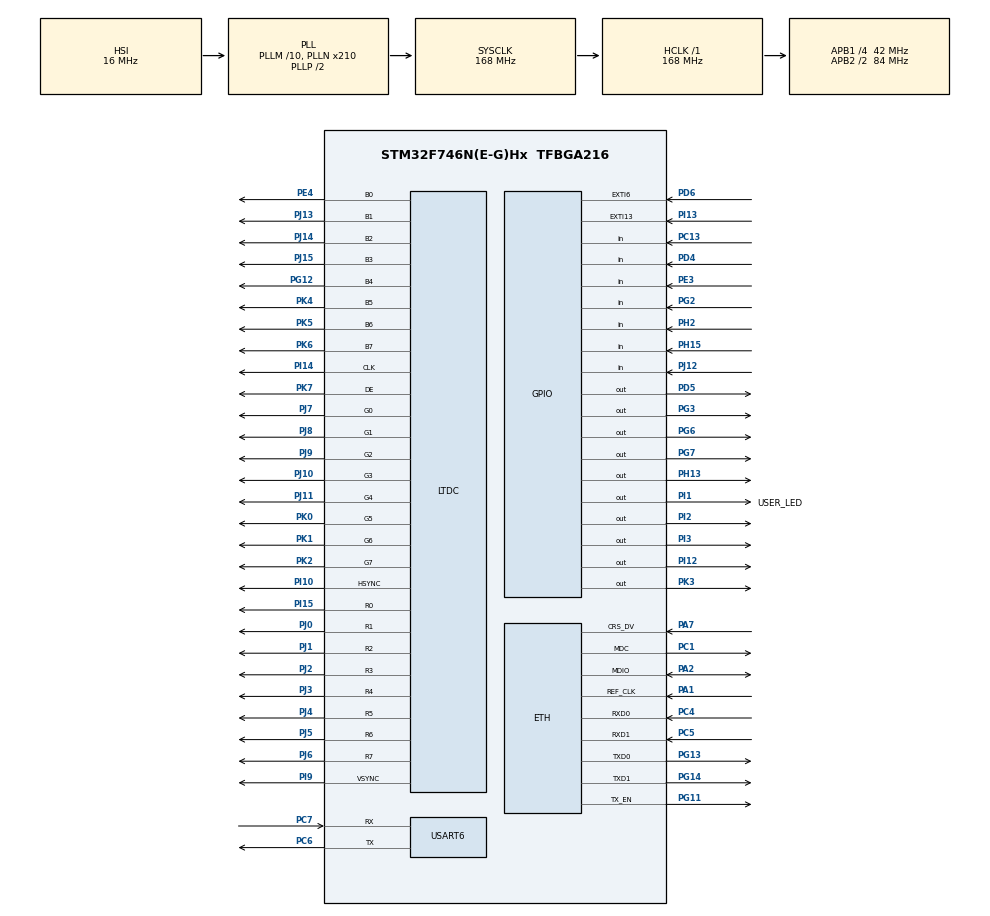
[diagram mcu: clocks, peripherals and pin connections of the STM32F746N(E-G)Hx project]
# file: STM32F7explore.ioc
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ETH.MediaInterface=ETH_MEDIA_INTERFACE_RMII
FREERTOS.Tasks01=defaultTask,0,128,StartDefaultTask,Default,NULL,Dynamic,NULL,NULL;BlinkyTask,-3,128,ExecBlinkyTask,Default,NULL,Dynamic,NULL,NULL
LWIP.Version=v2.0.0_Cube
Mcu.Family=STM32F7
Mcu.Name=STM32F746N(E-G)Hx
Mcu.Package=TFBGA216
NVIC.ETH_IRQn=true\:5\:0\:false\:false\:true\:true
NVIC.PriorityGroup=NVIC_PRIORITYGROUP_4
NVIC.TIM1_UP_TIM10_IRQn=true\:5\:0\:false\:false\:true\:true
NVIC.TimeBase=TIM1_UP_TIM10_IRQn
NVIC.TimeBaseIP=TIM1
PA0/WKUP.GPIO_Mode=GPIO_MODE_ANALOG
PA0/WKUP.GPIO_PuPd=GPIO_NOPULL
PA0/WKUP.Signal=ADCx_IN0
PA1.GPIO_Mode=GPIO_MODE_AF_PP
PA1.GPIO_PuPd=GPIO_NOPULL
PA1.GPIO_Speed=GPIO_SPEED_FREQ_VERY_HIGH
PA1.Mode=RMII
PA1.Signal=ETH_REF_CLK
PA10.GPIO_Mode=GPIO_MODE_AF_PP
PA10.GPIO_PuPd=GPIO_NOPULL
PA10.GPIO_Speed=GPIO_SPEED_FREQ_VERY_HIGH
PA10.Signal=USB_OTG_FS_ID
PA11.GPIO_Mode=GPIO_MODE_AF_PP
PA11.GPIO_PuPd=GPIO_NOPULL
PA11.GPIO_Speed=GPIO_SPEED_FREQ_VERY_HIGH
PA11.Signal=USB_OTG_FS_DM
PA12.GPIO_Mode=GPIO_MODE_AF_PP
PA12.GPIO_PuPd=GPIO_NOPULL
PA12.GPIO_Speed=GPIO_SPEED_FREQ_VERY_HIGH
PA12.Signal=USB_OTG_FS_DP
PA13.Signal=SYS_JTMS-SWDIO
PA14.Signal=SYS_JTCK-SWCLK
PA15.GPIO_ModeDefaultPP=GPIO_MODE_AF_PP
PA15.GPIO_PuPd=GPIO_NOPULL
PA15.GPIO_Speed=GPIO_SPEED_FREQ_LOW
PA15.Signal=S_TIM2_CH1_ETR
PA2.GPIO_Mode=GPIO_MODE_AF_PP
PA2.GPIO_PuPd=GPIO_NOPULL
PA2.GPIO_Speed=GPIO_SPEED_FREQ_VERY_HIGH
PA2.Mode=RMII
PA2.Signal=ETH_MDIO
PA3.GPIO_Mode=GPIO_MODE_AF_PP
PA3.GPIO_PuPd=GPIO_NOPULL
PA3.GPIO_Speed=GPIO_SPEED_FREQ_VERY_HIGH
PA3.Signal=USB_OTG_HS_ULPI_D0
PA4.GPIO_Mode=GPIO_MODE_AF_PP
PA4.GPIO_PuPd=GPIO_NOPULL
PA4.GPIO_Speed=GPIO_SPEED_FREQ_LOW
PA4.Signal=DCMI_HSYNC
PA5.GPIO_Mode=GPIO_MODE_AF_PP
PA5.GPIO_PuPd=GPIO_NOPULL
PA5.GPIO_Speed=GPIO_SPEED_FREQ_VERY_HIGH
PA5.Signal=USB_OTG_HS_ULPI_CK
PA6.Signal=DCMI_PIXCLK
PA7.GPIO_Mode=GPIO_MODE_AF_PP
PA7.GPIO_PuPd=GPIO_NOPULL
PA7.GPIO_Speed=GPIO_SPEED_FREQ_VERY_HIGH
PA7.Mode=RMII
PA7.Signal=ETH_CRS_DV
PA8.GPIO_ModeDefaultPP=GPIO_MODE_AF_PP
PA8.GPIO_PuPd=GPIO_NOPULL
PA8.GPIO_Speed=GPIO_SPEED_FREQ_LOW
PA8.Signal=S_TIM1_CH1
PA9.GPIO_Mode=GPIO_MODE_AF_PP
PA9.GPIO_PuPd=GPIO_NOPULL
PA9.GPIO_Speed=GPIO_SPEED_FREQ_VERY_HIGH
PA9.Signal=USART1_TX
PB0.GPIO_Mode=GPIO_MODE_AF_PP
PB0.GPIO_PuPd=GPIO_NOPULL
PB0.GPIO_Speed=GPIO_SPEED_FREQ_VERY_HIGH
PB0.Signal=USB_OTG_HS_ULPI_D1
PB1.GPIO_Mode=GPIO_MODE_AF_PP
PB1.GPIO_PuPd=GPIO_NOPULL
PB1.GPIO_Speed=GPIO_SPEED_FREQ_VERY_HIGH
PB1.Signal=USB_OTG_HS_ULPI_D2
PB10.GPIO_Mode=GPIO_MODE_AF_PP
PB10.GPIO_PuPd=GPIO_NOPULL
PB10.GPIO_Speed=GPIO_SPEED_FREQ_VERY_HIGH
PB10.Signal=USB_OTG_HS_ULPI_D3
PB11.GPIO_Mode=GPIO_MODE_AF_PP
PB11.GPIO_PuPd=GPIO_NOPULL
PB11.GPIO_Speed=GPIO_SPEED_FREQ_VERY_HIGH
PB11.Signal=USB_OTG_HS_ULPI_D4
PB12.GPIO_Mode=GPIO_MODE_AF_PP
PB12.GPIO_PuPd=GPIO_NOPULL
PB12.GPIO_Speed=GPIO_SPEED_FREQ_VERY_HIGH
PB12.Signal=USB_OTG_HS_ULPI_D5
PB13.GPIO_Mode=GPIO_MODE_AF_PP
PB13.GPIO_PuPd=GPIO_NOPULL
PB13.GPIO_Speed=GPIO_SPEED_FREQ_VERY_HIGH
PB13.Signal=USB_OTG_HS_ULPI_D6
PB14.GPIO_Mode=GPIO_MODE_AF_PP
PB14.GPIO_PuPd=GPIO_NOPULL
PB14.GPIO_Speed=GPIO_SPEED_FREQ_VERY_HIGH
PB14.Signal=SPI2_MISO
PB15.GPIO_Mode=GPIO_MODE_AF_PP
PB15.GPIO_PuPd=GPIO_NOPULL
PB15.GPIO_Speed=GPIO_SPEED_FREQ_VERY_HIGH
PB15.Signal=SPI2_MOSI
PB2.Signal=QUADSPI_CLK
PB3.Signal=SYS_JTDO-SWO
PB4.GPIO_ModeDefaultPP=GPIO_MODE_AF_PP
PB4.GPIO_PuPd=GPIO_NOPULL
PB4.GPIO_Speed=GPIO_SPEED_FREQ_LOW
PB4.Signal=S_TIM3_CH1
PB5.GPIO_Mode=GPIO_MODE_AF_PP
PB5.GPIO_PuPd=GPIO_NOPULL
PB5.GPIO_Speed=GPIO_SPEED_FREQ_VERY_HIGH
PB5.Signal=USB_OTG_HS_ULPI_D7
PB6.GPIO_Mode=GPIO_MODE_AF_PP
PB6.GPIO_PuPd=GPIO_NOPULL
PB6.GPIO_Speed=GPIO_SPEED_FREQ_VERY_HIGH
PB6.Signal=QUADSPI_BK1_NCS
PB7.GPIO_Mode=GPIO_MODE_AF_PP
PB7.GPIO_PuPd=GPIO_NOPULL
PB7.GPIO_Speed=GPIO_SPEED_FREQ_VERY_HIGH
PB7.Signal=USART1_RX
PB8.GPIO_Mode=GPIO_MODE_AF_OD
PB8.GPIO_PuPd=GPIO_NOPULL
PB8.GPIO_PuPdOD=GPIO_PULLUP
PB8.GPIO_Speed=GPIO_SPEED_FREQ_VERY_HIGH
PB8.Signal=I2C1_SCL
PB9.GPIO_Mode=GPIO_MODE_AF_OD
PB9.GPIO_PuPd=GPIO_NOPULL
PB9.GPIO_PuPdOD=GPIO_PULLUP
PB9.GPIO_Speed=GPIO_SPEED_FREQ_VERY_HIGH
PB9.Signal=I2C1_SDA
PC0.GPIO_Mode=GPIO_MODE_AF_PP
PC0.GPIO_PuPd=GPIO_NOPULL
PC0.GPIO_Speed=GPIO_SPEED_FREQ_VERY_HIGH
PC0.Signal=USB_OTG_HS_ULPI_STP
PC1.GPIO_Mode=GPIO_MODE_AF_PP
PC1.GPIO_PuPd=GPIO_NOPULL
PC1.GPIO_Speed=GPIO_SPEED_FREQ_VERY_HIGH
PC1.Mode=RMII
PC1.Signal=ETH_MDC
PC10.GPIO_Mode=GPIO_MODE_AF_PP
PC10.GPIO_PuPd=GPIO_NOPULL
PC10.GPIO_Speed_High_Default=GPIO_SPEED_FREQ_VERY_HIGH
PC10.Signal=SDMMC1_D2
PC11.GPIO_Mode=GPIO_MODE_AF_PP
PC11.GPIO_PuPd=GPIO_NOPULL
PC11.GPIO_Speed_High_Default=GPIO_SPEED_FREQ_VERY_HIGH
PC11.Signal=SDMMC1_D3
PC12.GPIO_Mode=GPIO_MODE_AF_PP
PC12.GPIO_PuPd=GPIO_NOPULL
PC12.GPIO_Speed_High_Default=GPIO_SPEED_FREQ_VERY_HIGH
PC12.Signal=SDMMC1_CK
PC13.GPIO_Mode=GPIO_MODE_INPUT
PC13.GPIO_PuPd=GPIO_NOPULL
PC13.Signal=GPIO_Input
PC14/OSC32_IN.Signal=RCC_OSC32_IN
PC15/OSC32_OUT.Signal=RCC_OSC32_OUT
PC2.GPIO_Mode=GPIO_MODE_AF_PP
PC2.GPIO_PuPd=GPIO_NOPULL
PC2.GPIO_Speed=GPIO_SPEED_FREQ_VERY_HIGH
PC2.Signal=USB_OTG_HS_ULPI_DIR
PC3.GPIO_Mode=GPIO_MODE_AF_PP
PC3.GPIO_PuPd=GPIO_NOPULL
PC3.GPIO_Speed_High_Default=GPIO_SPEED_FREQ_VERY_HIGH
PC3.Signal=FMC_SDCKE0
PC4.GPIO_Mode=GPIO_MODE_AF_PP
PC4.GPIO_PuPd=GPIO_NOPULL
PC4.GPIO_Speed=GPIO_SPEED_FREQ_VERY_HIGH
PC4.Mode=RMII
PC4.Signal=ETH_RXD0
PC5.GPIO_Mode=GPIO_MODE_AF_PP
PC5.GPIO_PuPd=GPIO_NOPULL
PC5.GPIO_Speed=GPIO_SPEED_FREQ_VERY_HIGH
PC5.Mode=RMII
PC5.Signal=ETH_RXD1
PC6.GPIO_Mode=GPIO_MODE_AF_PP
PC6.GPIO_PuPd=GPIO_NOPULL
PC6.GPIO_Speed=GPIO_SPEED_FREQ_VERY_HIGH
PC6.Mode=Asynchronous
PC6.Signal=USART6_TX
PC7.GPIO_Mode=GPIO_MODE_AF_PP
PC7.GPIO_PuPd=GPIO_NOPULL
PC7.GPIO_Speed=GPIO_SPEED_FREQ_VERY_HIGH
PC7.Mode=Asynchronous
PC7.Signal=USART6_RX
PC8.Signal=SDMMC1_D0
PC9.Signal=SDMMC1_D1
PD0.GPIO_Mode=GPIO_MODE_AF_PP
PD0.GPIO_PuPd=GPIO_NOPULL
PD0.GPIO_Speed_High_Default=GPIO_SPEED_FREQ_VERY_HIGH
PD0.Signal=FMC_D2_DA2
PD1.GPIO_Mode=GPIO_MODE_AF_PP
PD1.GPIO_PuPd=GPIO_NOPULL
PD1.GPIO_Speed_High_Default=GPIO_SPEED_FREQ_VERY_HIGH
PD1.Signal=FMC_D3_DA3
PD10.GPIO_Mode=GPIO_MODE_AF_PP
PD10.GPIO_PuPd=GPIO_NOPULL
PD10.GPIO_Speed_High_Default=GPIO_SPEED_FREQ_VERY_HIGH
PD10.Signal=FMC_D15_DA15
PD11.GPIO_Mode=GPIO_MODE_AF_PP
PD11.GPIO_PuPd=GPIO_NOPULL
PD11.GPIO_Speed=GPIO_SPEED_FREQ_VERY_HIGH
PD11.Signal=QUADSPI_BK1_IO0
PD12.GPIO_Mode=GPIO_MODE_AF_PP
PD12.GPIO_PuPd=GPIO_NOPULL
PD12.GPIO_Speed=GPIO_SPEED_FREQ_VERY_HIGH
PD12.Signal=QUADSPI_BK1_IO1
PD13.GPIO_Mode=GPIO_MODE_AF_PP
PD13.GPIO_PuPd=GPIO_NOPULL
PD13.GPIO_Speed=GPIO_SPEED_FREQ_VERY_HIGH
PD13.Signal=QUADSPI_BK1_IO3
PD14.GPIO_Mode=GPIO_MODE_AF_PP
PD14.GPIO_PuPd=GPIO_NOPULL
PD14.GPIO_Speed_High_Default=GPIO_SPEED_FREQ_VERY_HIGH
PD14.Signal=FMC_D0_DA0
PD15.GPIO_Mode=GPIO_MODE_AF_PP
PD15.GPIO_PuPd=GPIO_NOPULL
PD15.GPIO_Speed_High_Default=GPIO_SPEED_FREQ_VERY_HIGH
PD15.Signal=FMC_D1_DA1
PD2.GPIO_Mode=GPIO_MODE_AF_PP
PD2.GPIO_PuPd=GPIO_NOPULL
PD2.GPIO_Speed_High_Default=GPIO_SPEED_FREQ_VERY_HIGH
PD2.Signal=SDMMC1_CMD
PD3.GPIO_Mode=GPIO_MODE_AF_PP
PD3.GPIO_PuPd=GPIO_NOPULL
PD3.GPIO_Speed=GPIO_SPEED_FREQ_LOW
PD3.Signal=DCMI_D5
PD4.GPIO_Mode=GPIO_MODE_INPUT
PD4.GPIO_PuPd=GPIO_NOPULL
PD4.Signal=GPIO_Input
PD5.GPIO_ModeDefaultOutputPP=GPIO_MODE_OUTPUT_PP
PD5.GPIO_PuPd=GPIO_NOPULL
PD5.GPIO_Speed=GPIO_SPEED_FREQ_LOW
PD5.PinState=GPIO_PIN_RESET
PD5.Signal=GPIO_Output
PD6.GPIO_ModeDefaultEXTI=GPIO_MODE_IT_RISING
PD6.GPIO_PuPd=GPIO_NOPULL
PD6.Signal=GPXTI6
PD7.GPIO_Mode=GPIO_MODE_AF_PP
PD7.GPIO_PuPd=GPIO_NOPULL
PD7.GPIO_Speed=GPIO_SPEED_FREQ_LOW
PD7.Signal=SPDIFRX_IN0
PD8.GPIO_Mode=GPIO_MODE_AF_PP
PD8.GPIO_PuPd=GPIO_NOPULL
PD8.GPIO_Speed_High_Default=GPIO_SPEED_FREQ_VERY_HIGH
PD8.Signal=FMC_D13_DA13
PD9.GPIO_Mode=GPIO_MODE_AF_PP
PD9.GPIO_PuPd=GPIO_NOPULL
PD9.GPIO_Speed_High_Default=GPIO_SPEED_FREQ_VERY_HIGH
PD9.Signal=FMC_D14_DA14
PE0.GPIO_Mode=GPIO_MODE_AF_PP
PE0.GPIO_PuPd=GPIO_NOPULL
PE0.GPIO_Speed_High_Default=GPIO_SPEED_FREQ_VERY_HIGH
PE0.Signal=FMC_NBL0
PE1.GPIO_Mode=GPIO_MODE_AF_PP
PE1.GPIO_PuPd=GPIO_NOPULL
PE1.GPIO_Speed_High_Default=GPIO_SPEED_FREQ_VERY_HIGH
PE1.Signal=FMC_NBL1
PE10.GPIO_Mode=GPIO_MODE_AF_PP
PE10.GPIO_PuPd=GPIO_NOPULL
PE10.GPIO_Speed_High_Default=GPIO_SPEED_FREQ_VERY_HIGH
PE10.Signal=FMC_D7_DA7
PE11.GPIO_Mode=GPIO_MODE_AF_PP
PE11.GPIO_PuPd=GPIO_NOPULL
PE11.GPIO_Speed_High_Default=GPIO_SPEED_FREQ_VERY_HIGH
PE11.Signal=FMC_D8_DA8
PE12.GPIO_Mode=GPIO_MODE_AF_PP
PE12.GPIO_PuPd=GPIO_NOPULL
PE12.GPIO_Speed_High_Default=GPIO_SPEED_FREQ_VERY_HIGH
PE12.Signal=FMC_D9_DA9
PE13.GPIO_Mode=GPIO_MODE_AF_PP
PE13.GPIO_PuPd=GPIO_NOPULL
PE13.GPIO_Speed_High_Default=GPIO_SPEED_FREQ_VERY_HIGH
PE13.Signal=FMC_D10_DA10
PE14.GPIO_Mode=GPIO_MODE_AF_PP
PE14.GPIO_PuPd=GPIO_NOPULL
PE14.GPIO_Speed_High_Default=GPIO_SPEED_FREQ_VERY_HIGH
PE14.Signal=FMC_D11_DA11
PE15.GPIO_Mode=GPIO_MODE_AF_PP
PE15.GPIO_PuPd=GPIO_NOPULL
PE15.GPIO_Speed_High_Default=GPIO_SPEED_FREQ_VERY_HIGH
PE15.Signal=FMC_D12_DA12
PE2.GPIO_Mode=GPIO_MODE_AF_PP
PE2.GPIO_PuPd=GPIO_NOPULL
PE2.GPIO_Speed=GPIO_SPEED_FREQ_VERY_HIGH
PE2.Signal=QUADSPI_BK1_IO2
PE3.GPIO_Mode=GPIO_MODE_INPUT
PE3.GPIO_PuPd=GPIO_NOPULL
PE3.Signal=GPIO_Input
PE4.GPIO_Mode=GPIO_MODE_AF_PP
PE4.GPIO_PuPd=GPIO_NOPULL
PE4.GPIO_Speed=GPIO_SPEED_FREQ_LOW
PE4.Mode=RGB888
PE4.Signal=LTDC_B0
PE5.GPIO_Mode=GPIO_MODE_AF_PP
PE5.GPIO_PuPd=GPIO_NOPULL
PE5.GPIO_Speed=GPIO_SPEED_FREQ_LOW
PE5.Signal=DCMI_D6
PE6.GPIO_Mode=GPIO_MODE_AF_PP
PE6.GPIO_PuPd=GPIO_NOPULL
PE6.GPIO_Speed=GPIO_SPEED_FREQ_LOW
PE6.Signal=DCMI_D7
PE7.GPIO_Mode=GPIO_MODE_AF_PP
PE7.GPIO_PuPd=GPIO_NOPULL
PE7.GPIO_Speed_High_Default=GPIO_SPEED_FREQ_VERY_HIGH
PE7.Signal=FMC_D4_DA4
PE8.GPIO_Mode=GPIO_MODE_AF_PP
PE8.GPIO_PuPd=GPIO_NOPULL
PE8.GPIO_Speed_High_Default=GPIO_SPEED_FREQ_VERY_HIGH
PE8.Signal=FMC_D5_DA5
PE9.GPIO_Mode=GPIO_MODE_AF_PP
PE9.GPIO_PuPd=GPIO_NOPULL
PE9.GPIO_Speed_High_Default=GPIO_SPEED_FREQ_VERY_HIGH
PE9.Signal=FMC_D6_DA6
PF0.GPIO_Mode=GPIO_MODE_AF_PP
PF0.GPIO_PuPd=GPIO_NOPULL
PF0.GPIO_Speed_High_Default=GPIO_SPEED_FREQ_VERY_HIGH
PF0.Signal=FMC_A0
PF1.GPIO_Mode=GPIO_MODE_AF_PP
PF1.GPIO_PuPd=GPIO_NOPULL
PF1.GPIO_Speed_High_Default=GPIO_SPEED_FREQ_VERY_HIGH
PF1.Signal=FMC_A1
PF10.GPIO_Mode=GPIO_MODE_ANALOG
PF10.GPIO_PuPd=GPIO_NOPULL
PF10.Signal=ADC3_IN8
PF11.GPIO_Mode=GPIO_MODE_AF_PP
PF11.GPIO_PuPd=GPIO_NOPULL
PF11.GPIO_Speed_High_Default=GPIO_SPEED_FREQ_VERY_HIGH
PF11.Signal=FMC_SDNRAS
PF12.GPIO_Mode=GPIO_MODE_AF_PP
PF12.GPIO_PuPd=GPIO_NOPULL
PF12.GPIO_Speed_High_Default=GPIO_SPEED_FREQ_VERY_HIGH
PF12.Signal=FMC_A6
PF13.GPIO_Mode=GPIO_MODE_AF_PP
PF13.GPIO_PuPd=GPIO_NOPULL
PF13.GPIO_Speed_High_Default=GPIO_SPEED_FREQ_VERY_HIGH
PF13.Signal=FMC_A7
PF14.GPIO_Mode=GPIO_MODE_AF_PP
PF14.GPIO_PuPd=GPIO_NOPULL
PF14.GPIO_Speed_High_Default=GPIO_SPEED_FREQ_VERY_HIGH
PF14.Signal=FMC_A8
PF15.GPIO_Mode=GPIO_MODE_AF_PP
PF15.GPIO_PuPd=GPIO_NOPULL
PF15.GPIO_Speed_High_Default=GPIO_SPEED_FREQ_VERY_HIGH
PF15.Signal=FMC_A9
PF2.GPIO_Mode=GPIO_MODE_AF_PP
PF2.GPIO_PuPd=GPIO_NOPULL
PF2.GPIO_Speed_High_Default=GPIO_SPEED_FREQ_VERY_HIGH
PF2.Signal=FMC_A2
PF3.GPIO_Mode=GPIO_MODE_AF_PP
PF3.GPIO_PuPd=GPIO_NOPULL
PF3.GPIO_Speed_High_Default=GPIO_SPEED_FREQ_VERY_HIGH
PF3.Signal=FMC_A3
PF4.GPIO_Mode=GPIO_MODE_AF_PP
PF4.GPIO_PuPd=GPIO_NOPULL
PF4.GPIO_Speed_High_Default=GPIO_SPEED_FREQ_VERY_HIGH
PF4.Signal=FMC_A4
PF5.GPIO_Mode=GPIO_MODE_AF_PP
PF5.GPIO_PuPd=GPIO_NOPULL
PF5.GPIO_Speed_High_Default=GPIO_SPEED_FREQ_VERY_HIGH
PF5.Signal=FMC_A5
PF6.GPIO_Mode=GPIO_MODE_ANALOG
PF6.GPIO_PuPd=GPIO_NOPULL
PF6.Signal=ADC3_IN4
PF7.GPIO_Mode=GPIO_MODE_ANALOG
PF7.GPIO_PuPd=GPIO_NOPULL
PF7.Signal=ADC3_IN5
PF8.GPIO_Mode=GPIO_MODE_ANALOG
PF8.GPIO_PuPd=GPIO_NOPULL
PF8.Signal=ADC3_IN6
PF9.GPIO_Mode=GPIO_MODE_ANALOG
PF9.GPIO_PuPd=GPIO_NOPULL
PF9.Signal=ADC3_IN7
PG0.GPIO_Mode=GPIO_MODE_AF_PP
PG0.GPIO_PuPd=GPIO_NOPULL
PG0.GPIO_Speed_High_Default=GPIO_SPEED_FREQ_VERY_HIGH
PG0.Signal=FMC_A10
PG1.GPIO_Mode=GPIO_MODE_AF_PP
PG1.GPIO_PuPd=GPIO_NOPULL
PG1.GPIO_Speed_High_Default=GPIO_SPEED_FREQ_VERY_HIGH
PG1.Signal=FMC_A11
PG10.GPIO_Mode=GPIO_MODE_AF_PP
PG10.GPIO_PuPd=GPIO_NOPULL
PG10.GPIO_Speed=GPIO_SPEED_FREQ_LOW
PG10.Signal=SAI2_SD_B
PG11.GPIO_Mode=GPIO_MODE_AF_PP
PG11.GPIO_PuPd=GPIO_NOPULL
PG11.GPIO_Speed=GPIO_SPEED_FREQ_VERY_HIGH
PG11.Mode=RMII
PG11.Signal=ETH_TX_EN
PG12.GPIO_Mode=GPIO_MODE_AF_PP
PG12.GPIO_PuPd=GPIO_NOPULL
PG12.GPIO_Speed=GPIO_SPEED_FREQ_LOW
PG12.Mode=RGB888
PG12.Signal=LTDC_B4
PG13.GPIO_Mode=GPIO_MODE_AF_PP
PG13.GPIO_PuPd=GPIO_NOPULL
PG13.GPIO_Speed=GPIO_SPEED_FREQ_VERY_HIGH
PG13.Mode=RMII
PG13.Signal=ETH_TXD0
PG14.GPIO_Mode=GPIO_MODE_AF_PP
PG14.GPIO_PuPd=GPIO_NOPULL
PG14.GPIO_Speed=GPIO_SPEED_FREQ_VERY_HIGH
PG14.Mode=RMII
PG14.Signal=ETH_TXD1
PG15.GPIO_Mode=GPIO_MODE_AF_PP
PG15.GPIO_PuPd=GPIO_NOPULL
PG15.GPIO_Speed_High_Default=GPIO_SPEED_FREQ_VERY_HIGH
PG15.Signal=FMC_SDNCAS
PG2.GPIO_Mode=GPIO_MODE_INPUT
PG2.GPIO_PuPd=GPIO_NOPULL
PG2.Signal=GPIO_Input
PG3.GPIO_ModeDefaultOutputPP=GPIO_MODE_OUTPUT_PP
PG3.GPIO_PuPd=GPIO_NOPULL
PG3.GPIO_Speed=GPIO_SPEED_FREQ_LOW
PG3.PinState=GPIO_PIN_RESET
PG3.Signal=GPIO_Output
PG4.GPIO_Mode=GPIO_MODE_AF_PP
PG4.GPIO_PuPd=GPIO_NOPULL
PG4.GPIO_Speed_High_Default=GPIO_SPEED_FREQ_VERY_HIGH
PG4.Signal=FMC_A14_BA0
PG5.GPIO_Mode=GPIO_MODE_AF_PP
PG5.GPIO_PuPd=GPIO_NOPULL
PG5.GPIO_Speed_High_Default=GPIO_SPEED_FREQ_VERY_HIGH
PG5.Signal=FMC_A15_BA1
PG6.GPIO_ModeDefaultOutputPP=GPIO_MODE_OUTPUT_PP
PG6.GPIO_PuPd=GPIO_NOPULL
PG6.GPIO_Speed=GPIO_SPEED_FREQ_LOW
PG6.PinState=GPIO_PIN_RESET
PG6.Signal=GPIO_Output
PG7.GPIO_ModeDefaultOutputPP=GPIO_MODE_OUTPUT_PP
PG7.GPIO_PuPd=GPIO_NOPULL
PG7.GPIO_Speed=GPIO_SPEED_FREQ_LOW
PG7.PinState=GPIO_PIN_RESET
PG7.Signal=GPIO_Output
PG8.GPIO_Mode=GPIO_MODE_AF_PP
PG8.GPIO_PuPd=GPIO_NOPULL
PG8.GPIO_Speed_High_Default=GPIO_SPEED_FREQ_VERY_HIGH
PG8.Signal=FMC_SDCLK
PG9.GPIO_Mode=GPIO_MODE_AF_PP
PG9.GPIO_PuPd=GPIO_NOPULL
PG9.GPIO_Speed=GPIO_SPEED_FREQ_LOW
PG9.Signal=DCMI_VSYNC
PH0/OSC_IN.Signal=RCC_OSC_IN
PH1/OSC_OUT.Signal=RCC_OSC_OUT
PH10.GPIO_Mode=GPIO_MODE_AF_PP
PH10.GPIO_PuPd=GPIO_NOPULL
PH10.GPIO_Speed=GPIO_SPEED_FREQ_LOW
PH10.Signal=DCMI_D1
PH11.GPIO_Mode=GPIO_MODE_AF_PP
PH11.GPIO_PuPd=GPIO_NOPULL
PH11.GPIO_Speed=GPIO_SPEED_FREQ_LOW
PH11.Signal=DCMI_D2
PH12.GPIO_Mode=GPIO_MODE_AF_PP
PH12.GPIO_PuPd=GPIO_NOPULL
PH12.GPIO_Speed=GPIO_SPEED_FREQ_LOW
PH12.Signal=DCMI_D3
PH13.GPIO_ModeDefaultOutputPP=GPIO_MODE_OUTPUT_PP
PH13.GPIO_PuPd=GPIO_NOPULL
PH13.GPIO_Speed=GPIO_SPEED_FREQ_LOW
PH13.PinState=GPIO_PIN_RESET
PH13.Signal=GPIO_Output
PH14.GPIO_Mode=GPIO_MODE_AF_PP
PH14.GPIO_PuPd=GPIO_NOPULL
PH14.GPIO_Speed=GPIO_SPEED_FREQ_LOW
PH14.Signal=DCMI_D4
PH15.GPIO_Mode=GPIO_MODE_INPUT
PH15.GPIO_PuPd=GPIO_NOPULL
PH15.Signal=GPIO_Input
PH2.GPIO_Mode=GPIO_MODE_INPUT
PH2.GPIO_PuPd=GPIO_NOPULL
PH2.Signal=GPIO_Input
PH3.GPIO_Mode=GPIO_MODE_AF_PP
PH3.GPIO_PuPd=GPIO_NOPULL
PH3.GPIO_Speed_High_Default=GPIO_SPEED_FREQ_VERY_HIGH
PH3.Signal=FMC_SDNE0
PH4.GPIO_Mode=GPIO_MODE_AF_PP
PH4.GPIO_PuPd=GPIO_NOPULL
PH4.GPIO_Speed=GPIO_SPEED_FREQ_VERY_HIGH
PH4.Signal=USB_OTG_HS_ULPI_NXT
PH5.GPIO_Mode=GPIO_MODE_AF_PP
PH5.GPIO_PuPd=GPIO_NOPULL
PH5.GPIO_Speed_High_Default=GPIO_SPEED_FREQ_VERY_HIGH
PH5.Signal=FMC_SDNWE
PH6.GPIO_ModeDefaultPP=GPIO_MODE_AF_PP
PH6.GPIO_PuPd=GPIO_NOPULL
PH6.GPIO_Speed=GPIO_SPEED_FREQ_LOW
PH6.Signal=S_TIM12_CH1
PH7.GPIO_Mode=GPIO_MODE_AF_OD
PH7.GPIO_PuPdOD=GPIO_PULLUP
PH7.GPIO_Speed=GPIO_SPEED_FREQ_VERY_HIGH
PH7.Signal=I2C3_SCL
PH8.GPIO_Mode=GPIO_MODE_AF_OD
PH8.GPIO_PuPdOD=GPIO_PULLUP
PH8.GPIO_Speed=GPIO_SPEED_FREQ_VERY_HIGH
PH8.Signal=I2C3_SDA
PH9.GPIO_Mode=GPIO_MODE_AF_PP
PH9.GPIO_PuPd=GPIO_NOPULL
PH9.GPIO_Speed=GPIO_SPEED_FREQ_LOW
PH9.Signal=DCMI_D0
PI0.GPIO_ModeDefaultPP=GPIO_MODE_AF_PP
PI0.GPIO_PuPd=GPIO_NOPULL
PI0.GPIO_Speed=GPIO_SPEED_FREQ_LOW
PI0.Signal=S_TIM5_CH4
PI1.GPIO_Label=USER_LED
PI1.GPIO_ModeDefaultOutputPP=GPIO_MODE_OUTPUT_PP
PI1.GPIO_PuPd=GPIO_NOPULL
PI1.GPIO_Speed=GPIO_SPEED_FREQ_LOW
PI1.PinState=GPIO_PIN_RESET
PI1.Signal=GPIO_Output
PI10.GPIO_Mode=GPIO_MODE_AF_PP
PI10.GPIO_PuPd=GPIO_NOPULL
PI10.GPIO_Speed=GPIO_SPEED_FREQ_LOW
PI10.Mode=RGB888
PI10.Signal=LTDC_HSYNC
PI12.GPIO_ModeDefaultOutputPP=GPIO_MODE_OUTPUT_PP
PI12.GPIO_PuPd=GPIO_NOPULL
PI12.GPIO_Speed=GPIO_SPEED_FREQ_LOW
PI12.PinState=GPIO_PIN_RESET
PI12.Signal=GPIO_Output
PI13.GPIO_ModeDefaultEXTI=GPIO_MODE_IT_RISING
PI13.GPIO_PuPd=GPIO_NOPULL
PI13.Signal=GPXTI13
PI14.GPIO_Mode=GPIO_MODE_AF_PP
PI14.GPIO_PuPd=GPIO_NOPULL
PI14.GPIO_Speed=GPIO_SPEED_FREQ_LOW
PI14.Mode=RGB888
PI14.Signal=LTDC_CLK
PI15.GPIO_Mode=GPIO_MODE_AF_PP
PI15.GPIO_PuPd=GPIO_NOPULL
PI15.GPIO_Speed=GPIO_SPEED_FREQ_LOW
PI15.Mode=RGB888
PI15.Signal=LTDC_R0
PI2.GPIO_ModeDefaultOutputPP=GPIO_MODE_OUTPUT_PP
PI2.GPIO_PuPd=GPIO_NOPULL
PI2.GPIO_Speed=GPIO_SPEED_FREQ_LOW
PI2.PinState=GPIO_PIN_RESET
PI2.Signal=GPIO_Output
PI3.GPIO_ModeDefaultOutputPP=GPIO_MODE_OUTPUT_PP
PI3.GPIO_PuPd=GPIO_NOPULL
PI3.GPIO_Speed=GPIO_SPEED_FREQ_LOW
PI3.PinState=GPIO_PIN_RESET
PI3.Signal=GPIO_Output
PI4.GPIO_Mode=GPIO_MODE_AF_PP
PI4.GPIO_PuPd=GPIO_NOPULL
PI4.GPIO_Speed=GPIO_SPEED_FREQ_LOW
PI4.Signal=SAI2_MCLK_A
PI5.GPIO_Mode=GPIO_MODE_AF_PP
PI5.GPIO_PuPd=GPIO_NOPULL
PI5.GPIO_Speed=GPIO_SPEED_FREQ_LOW
PI5.Signal=SAI2_SCK_A
PI6.GPIO_Mode=GPIO_MODE_AF_PP
PI6.GPIO_PuPd=GPIO_NOPULL
PI6.GPIO_Speed=GPIO_SPEED_FREQ_LOW
PI6.Signal=SAI2_SD_A
PI7.GPIO_Mode=GPIO_MODE_AF_PP
PI7.GPIO_PuPd=GPIO_NOPULL
PI7.GPIO_Speed=GPIO_SPEED_FREQ_LOW
PI7.Signal=SAI2_FS_A
PI8.Signal=RTC_TS
PI9.GPIO_Mode=GPIO_MODE_AF_PP
PI9.GPIO_PuPd=GPIO_NOPULL
PI9.GPIO_Speed=GPIO_SPEED_FREQ_LOW
PI9.Mode=RGB888
PI9.Signal=LTDC_VSYNC
PJ0.GPIO_Mode=GPIO_MODE_AF_PP
PJ0.GPIO_PuPd=GPIO_NOPULL
PJ0.GPIO_Speed=GPIO_SPEED_FREQ_LOW
PJ0.Mode=RGB888
PJ0.Signal=LTDC_R1
PJ1.GPIO_Mode=GPIO_MODE_AF_PP
PJ1.GPIO_PuPd=GPIO_NOPULL
PJ1.GPIO_Speed=GPIO_SPEED_FREQ_LOW
PJ1.Mode=RGB888
PJ1.Signal=LTDC_R2
PJ10.GPIO_Mode=GPIO_MODE_AF_PP
PJ10.GPIO_PuPd=GPIO_NOPULL
PJ10.GPIO_Speed=GPIO_SPEED_FREQ_LOW
PJ10.Mode=RGB888
PJ10.Signal=LTDC_G3
PJ11.GPIO_Mode=GPIO_MODE_AF_PP
PJ11.GPIO_PuPd=GPIO_NOPULL
PJ11.GPIO_Speed=GPIO_SPEED_FREQ_LOW
PJ11.Mode=RGB888
PJ11.Signal=LTDC_G4
PJ12.GPIO_Mode=GPIO_MODE_INPUT
PJ12.GPIO_PuPd=GPIO_NOPULL
PJ12.Signal=GPIO_Input
PJ13.GPIO_Mode=GPIO_MODE_AF_PP
PJ13.GPIO_PuPd=GPIO_NOPULL
PJ13.GPIO_Speed=GPIO_SPEED_FREQ_LOW
PJ13.Mode=RGB888
PJ13.Signal=LTDC_B1
PJ14.GPIO_Mode=GPIO_MODE_AF_PP
PJ14.GPIO_PuPd=GPIO_NOPULL
PJ14.GPIO_Speed=GPIO_SPEED_FREQ_LOW
PJ14.Mode=RGB888
PJ14.Signal=LTDC_B2
PJ15.GPIO_Mode=GPIO_MODE_AF_PP
PJ15.GPIO_PuPd=GPIO_NOPULL
PJ15.GPIO_Speed=GPIO_SPEED_FREQ_LOW
PJ15.Mode=RGB888
PJ15.Signal=LTDC_B3
PJ2.GPIO_Mode=GPIO_MODE_AF_PP
PJ2.GPIO_PuPd=GPIO_NOPULL
PJ2.GPIO_Speed=GPIO_SPEED_FREQ_LOW
PJ2.Mode=RGB888
PJ2.Signal=LTDC_R3
PJ3.GPIO_Mode=GPIO_MODE_AF_PP
PJ3.GPIO_PuPd=GPIO_NOPULL
PJ3.GPIO_Speed=GPIO_SPEED_FREQ_LOW
PJ3.Mode=RGB888
PJ3.Signal=LTDC_R4
PJ4.GPIO_Mode=GPIO_MODE_AF_PP
PJ4.GPIO_PuPd=GPIO_NOPULL
PJ4.GPIO_Speed=GPIO_SPEED_FREQ_LOW
PJ4.Mode=RGB888
PJ4.Signal=LTDC_R5
PJ5.GPIO_Mode=GPIO_MODE_AF_PP
PJ5.GPIO_PuPd=GPIO_NOPULL
PJ5.GPIO_Speed=GPIO_SPEED_FREQ_LOW
PJ5.Mode=RGB888
PJ5.Signal=LTDC_R6
PJ6.GPIO_Mode=GPIO_MODE_AF_PP
PJ6.GPIO_PuPd=GPIO_NOPULL
PJ6.GPIO_Speed=GPIO_SPEED_FREQ_LOW
PJ6.Mode=RGB888
PJ6.Signal=LTDC_R7
PJ7.GPIO_Mode=GPIO_MODE_AF_PP
PJ7.GPIO_PuPd=GPIO_NOPULL
PJ7.GPIO_Speed=GPIO_SPEED_FREQ_LOW
PJ7.Mode=RGB888
PJ7.Signal=LTDC_G0
PJ8.GPIO_Mode=GPIO_MODE_AF_PP
PJ8.GPIO_PuPd=GPIO_NOPULL
PJ8.GPIO_Speed=GPIO_SPEED_FREQ_LOW
PJ8.Mode=RGB888
PJ8.Signal=LTDC_G1
PJ9.GPIO_Mode=GPIO_MODE_AF_PP
PJ9.GPIO_PuPd=GPIO_NOPULL
PJ9.GPIO_Speed=GPIO_SPEED_FREQ_LOW
PJ9.Mode=RGB888
PJ9.Signal=LTDC_G2
PK0.GPIO_Mode=GPIO_MODE_AF_PP
PK0.GPIO_PuPd=GPIO_NOPULL
PK0.GPIO_Speed=GPIO_SPEED_FREQ_LOW
PK0.Mode=RGB888
PK0.Signal=LTDC_G5
PK1.GPIO_Mode=GPIO_MODE_AF_PP
PK1.GPIO_PuPd=GPIO_NOPULL
PK1.GPIO_Speed=GPIO_SPEED_FREQ_LOW
PK1.Mode=RGB888
PK1.Signal=LTDC_G6
PK2.GPIO_Mode=GPIO_MODE_AF_PP
PK2.GPIO_PuPd=GPIO_NOPULL
PK2.GPIO_Speed=GPIO_SPEED_FREQ_LOW
PK2.Mode=RGB888
PK2.Signal=LTDC_G7
PK3.GPIO_ModeDefaultOutputPP=GPIO_MODE_OUTPUT_PP
PK3.GPIO_PuPd=GPIO_NOPULL
PK3.GPIO_Speed=GPIO_SPEED_FREQ_LOW
PK3.PinState=GPIO_PIN_RESET
PK3.Signal=GPIO_Output
PK4.GPIO_Mode=GPIO_MODE_AF_PP
PK4.GPIO_PuPd=GPIO_NOPULL
PK4.GPIO_Speed=GPIO_SPEED_FREQ_LOW
PK4.Mode=RGB888
PK4.Signal=LTDC_B5
PK5.GPIO_Mode=GPIO_MODE_AF_PP
PK5.GPIO_PuPd=GPIO_NOPULL
PK5.GPIO_Speed=GPIO_SPEED_FREQ_LOW
PK5.Mode=RGB888
PK5.Signal=LTDC_B6
PK6.GPIO_Mode=GPIO_MODE_AF_PP
PK6.GPIO_PuPd=GPIO_NOPULL
PK6.GPIO_Speed=GPIO_SPEED_FREQ_LOW
PK6.Mode=RGB888
PK6.Signal=LTDC_B7
PK7.GPIO_Mode=GPIO_MODE_AF_PP
PK7.GPIO_PuPd=GPIO_NOPULL
PK7.GPIO_Speed=GPIO_SPEED_FREQ_LOW
PK7.Mode=RGB888
PK7.Signal=LTDC_DE
ProjectManager.HeapSize=0x200
ProjectManager.StackSize=0x400
ProjectManager.TargetToolchain=SW4STM32
RCC.AHBFreq_Value=168000000
RCC.APB1CLKDivider=RCC_HCLK_DIV4
RCC.APB1Freq_Value=42000000
RCC.APB1TimFreq_Value=84000000
RCC.APB2CLKDivider=RCC_HCLK_DIV2
RCC.APB2Freq_Value=84000000
RCC.APB2TimFreq_Value=168000000
RCC.CortexFreq_Value=168000000
RCC.HCLKFreq_Value=168000000
RCC.HSE_VALUE=25000000
RCC.HSI_VALUE=16000000
RCC.LSE_VALUE=32768
RCC.PLLM=10
RCC.PLLN=210
RCC.PLLSourceVirtual=RCC_PLLSOURCE_HSI
RCC.SYSCLKFreq_VALUE=168000000
RCC.SYSCLKSource=RCC_SYSCLKSOURCE_PLLCLK
RCC.USBFreq_Value=168000000
RCC.VCOOutputFreq_Value=336000000
SH.ADCx_IN0.0=ADC3_IN0
SH.FMC_A0.0=FMC_A0
SH.FMC_A1.0=FMC_A1
SH.FMC_A10.0=FMC_A10
SH.FMC_A11.0=FMC_A11
SH.FMC_A14_BA0.0=FMC_BA0
SH.FMC_A15_BA1.0=FMC_BA1
SH.FMC_A2.0=FMC_A2
SH.FMC_A3.0=FMC_A3
SH.FMC_A4.0=FMC_A4
SH.FMC_A5.0=FMC_A5
SH.FMC_A6.0=FMC_A6
SH.FMC_A7.0=FMC_A7
SH.FMC_A8.0=FMC_A8
SH.FMC_A9.0=FMC_A9
SH.FMC_D0_DA0.0=FMC_D0
SH.FMC_D10_DA10.0=FMC_D10
SH.FMC_D11_DA11.0=FMC_D11
SH.FMC_D12_DA12.0=FMC_D12
SH.FMC_D13_DA13.0=FMC_D13
SH.FMC_D14_DA14.0=FMC_D14
SH.FMC_D15_DA15.0=FMC_D15
SH.FMC_D1_DA1.0=FMC_D1
SH.FMC_D2_DA2.0=FMC_D2
SH.FMC_D3_DA3.0=FMC_D3
SH.FMC_D4_DA4.0=FMC_D4
SH.FMC_D5_DA5.0=FMC_D5
SH.FMC_D6_DA6.0=FMC_D6
SH.FMC_D7_DA7.0=FMC_D7
SH.FMC_D8_DA8.0=FMC_D8
SH.FMC_D9_DA9.0=FMC_D9
SH.FMC_NBL0.0=FMC_NBL0
SH.FMC_NBL1.0=FMC_NBL1
SH.FMC_SDCLK.0=FMC_SDCLK
SH.FMC_SDNCAS.0=FMC_SDNCAS
SH.FMC_SDNRAS.0=FMC_SDNRAS
SH.FMC_SDNWE.0=FMC_SDNWE
SH.S_TIM12_CH1.0=TIM12_CH1
SH.S_TIM1_CH1.0=TIM1_CH1
SH.S_TIM2_CH1_ETR.0=TIM2_CH1
SH.S_TIM3_CH1.0=TIM3_CH1
SH.S_TIM5_CH4.0=TIM5_CH4
VP_DMA2D_VS_DMA2D.Mode=DMA2D_Activate
VP_FREERTOS_VS_ENABLE.Mode=Enabled
VP_LWIP_VS_Enabled.Mode=Enabled
VP_SYS_VS_tim1.Mode=TIM1
board=STM32F746G-DISCO

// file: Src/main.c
/**
  ******************************************************************************
  * File Name          : main.c
  * Description        : Main program body
  ******************************************************************************
  *
  * Copyright (c) 2017 STMicroelectronics International N.V.
  * All rights reserved.
  *
  * Redistribution and use in source and binary forms, with or without
  * modification, are permitted, provided that the following conditions are met:
  *
  * 1. Redistribution of source code must retain the above copyright notice,
  *    this list of conditions and the following disclaimer.
  * 2. Redistributions in binary form must reproduce the above copyright notice,
  *    this list of conditions and the following disclaimer in the documentation
  *    and/or other materials provided with the distribution.
  * 3. Neither the name of STMicroelectronics nor the names of other
  *    contributors to this software may be used to endorse or promote products
  *    derived from this software without specific written permission.
  * 4. This software, including modifications and/or derivative works of this
  *    software, must execute solely and exclusively on microcontroller or
  *    microprocessor devices manufactured by or for STMicroelectronics.
  * 5. Redistribution and use of this software other than as permitted under
  *    this license is void and will automatically terminate your rights under
  *    this license.
  *
  * THIS SOFTWARE IS PROVIDED BY STMICROELECTRONICS AND CONTRIBUTORS "AS IS"
  * AND ANY EXPRESS, IMPLIED OR STATUTORY WARRANTIES, INCLUDING, BUT NOT
  * LIMITED TO, THE IMPLIED WARRANTIES OF MERCHANTABILITY, FITNESS FOR A
  * PARTICULAR PURPOSE AND NON-INFRINGEMENT OF THIRD PARTY INTELLECTUAL PROPERTY
  * RIGHTS ARE DISCLAIMED TO THE FULLEST EXTENT PERMITTED BY LAW. IN NO EVENT
  * SHALL STMICROELECTRONICS OR CONTRIBUTORS BE LIABLE FOR ANY DIRECT, INDIRECT,
  * INCIDENTAL, SPECIAL, EXEMPLARY, OR CONSEQUENTIAL DAMAGES (INCLUDING, BUT NOT
  * LIMITED TO, PROCUREMENT OF SUBSTITUTE GOODS OR SERVICES; LOSS OF USE, DATA,
  * OR PROFITS; OR BUSINESS INTERRUPTION) HOWEVER CAUSED AND ON ANY THEORY OF
  * LIABILITY, WHETHER IN CONTRACT, STRICT LIABILITY, OR TORT (INCLUDING
  * NEGLIGENCE OR OTHERWISE) ARISING IN ANY WAY OUT OF THE USE OF THIS SOFTWARE,
  * EVEN IF ADVISED OF THE POSSIBILITY OF SUCH DAMAGE.
  *
  ******************************************************************************
  */
#include "main.h"
#include "stm32f7xx_hal.h"
#include "cmsis_os.h"
#include "dma2d.h"
#include "ltdc.h"
#include "lwip.h"
#include "usart.h"
#include "gpio.h"
#include "lcd_log.h"

/* USER CODE BEGIN PV */
/* Private variables ---------------------------------------------------------*/

/* USER CODE END PV */

void SystemClock_Config(void);
void Error_Handler(void);
void MX_FREERTOS_Init(void);

/* USER CODE BEGIN PFP */
/* Private function prototypes -----------------------------------------------*/

/* USER CODE END PFP */

/* USER CODE BEGIN 0 */
/**
  * @brief  Initializes the STM327546G-Discovery's LCD  resources.
  * @param  None
  * @retval None
  */
static void BSP_Config(void)
{
  /* Initialize the LCD */
  BSP_LCD_Init();

  /* Initialize the LCD Layers */
  BSP_LCD_LayerDefaultInit(1, LCD_FB_START_ADDRESS);

  /* Set LCD Foreground Layer  */
  BSP_LCD_SelectLayer(1);

  BSP_LCD_SetFont(&LCD_DEFAULT_FONT);

  /* Initialize LCD Log module */
  LCD_LOG_Init();

  /* Show Header and Footer texts */
  LCD_LOG_SetHeader((uint8_t *)"Webserver Application Netconn API");
  LCD_LOG_SetFooter((uint8_t *)"STM32746G-DISCO board");

  LCD_UsrLog ((char *)"  State: Ethernet Initialization ...\n");
}

/* USER CODE END 0 */

int main(void)
{

  /* MCU Configuration----------------------------------------------------------*/

  /* Reset of all peripherals, Initializes the Flash interface and the Systick. */
  HAL_Init();

  /* Configure the system clock */
  SystemClock_Config();

  /* Initialize all configured peripherals */
  MX_GPIO_Init();
  MX_LTDC_Init();
  MX_DMA2D_Init();
  MX_USART6_UART_Init();

  /* USER CODE BEGIN 2 */

  /* Initialize LCD */
  BSP_Config();

  /* USER CODE END 2 */

  /* Call init function for freertos objects (in freertos.c) */
  MX_FREERTOS_Init();

  /* Start scheduler */
  osKernelStart();

  /* We should never get here as control is now taken by the scheduler */

  /* Infinite loop */
  while (1)
  {

  }

}

/** System Clock Configuration
*/
void SystemClock_Config(void)
{

  RCC_OscInitTypeDef RCC_OscInitStruct;
  RCC_ClkInitTypeDef RCC_ClkInitStruct;
  RCC_PeriphCLKInitTypeDef PeriphClkInitStruct;

    /**Configure the main internal regulator output voltage
    */
  __HAL_RCC_PWR_CLK_ENABLE();

  __HAL_PWR_VOLTAGESCALING_CONFIG(PWR_REGULATOR_VOLTAGE_SCALE2);

    /**Initializes the CPU, AHB and APB busses clocks
    */
  RCC_OscInitStruct.OscillatorType = RCC_OSCILLATORTYPE_HSI;
  RCC_OscInitStruct.HSIState = RCC_HSI_ON;
  RCC_OscInitStruct.HSICalibrationValue = 16;
  RCC_OscInitStruct.PLL.PLLState = RCC_PLL_ON;
  RCC_OscInitStruct.PLL.PLLSource = RCC_PLLSOURCE_HSI;
  RCC_OscInitStruct.PLL.PLLM = 10;
  RCC_OscInitStruct.PLL.PLLN = 210;
  RCC_OscInitStruct.PLL.PLLP = RCC_PLLP_DIV2;
  RCC_OscInitStruct.PLL.PLLQ = 2;
  if (HAL_RCC_OscConfig(&RCC_OscInitStruct) != HAL_OK)
  {
    Error_Handler();
  }

    /**Initializes the CPU, AHB and APB busses clocks
    */
  RCC_ClkInitStruct.ClockType = RCC_CLOCKTYPE_HCLK|RCC_CLOCKTYPE_SYSCLK
                              |RCC_CLOCKTYPE_PCLK1|RCC_CLOCKTYPE_PCLK2;
  RCC_ClkInitStruct.SYSCLKSource = RCC_SYSCLKSOURCE_PLLCLK;
  RCC_ClkInitStruct.AHBCLKDivider = RCC_SYSCLK_DIV1;
  RCC_ClkInitStruct.APB1CLKDivider = RCC_HCLK_DIV4;
  RCC_ClkInitStruct.APB2CLKDivider = RCC_HCLK_DIV2;

  if (HAL_RCC_ClockConfig(&RCC_ClkInitStruct, FLASH_LATENCY_5) != HAL_OK)
  {
    Error_Handler();
  }

  PeriphClkInitStruct.PeriphClockSelection = RCC_PERIPHCLK_LTDC|RCC_PERIPHCLK_USART6;
  PeriphClkInitStruct.PLLSAI.PLLSAIN = 192;
  PeriphClkInitStruct.PLLSAI.PLLSAIR = 2;
  PeriphClkInitStruct.PLLSAI.PLLSAIQ = 2;
  PeriphClkInitStruct.PLLSAI.PLLSAIP = RCC_PLLSAIP_DIV2;
  PeriphClkInitStruct.PLLSAIDivQ = 1;
  PeriphClkInitStruct.PLLSAIDivR = RCC_PLLSAIDIVR_2;
  PeriphClkInitStruct.Usart6ClockSelection = RCC_USART6CLKSOURCE_PCLK2;
  if (HAL_RCCEx_PeriphCLKConfig(&PeriphClkInitStruct) != HAL_OK)
  {
    Error_Handler();
  }

    /**Configure the Systick interrupt time
    */
  HAL_SYSTICK_Config(HAL_RCC_GetHCLKFreq()/1000);

    /**Configure the Systick
    */
  HAL_SYSTICK_CLKSourceConfig(SYSTICK_CLKSOURCE_HCLK);

  /* SysTick_IRQn interrupt configuration */
  HAL_NVIC_SetPriority(SysTick_IRQn, 15, 0);
}

void HAL_TIM_PeriodElapsedCallback(TIM_HandleTypeDef *htim)
{
  if (htim->Instance == TIM1) {
    HAL_IncTick();
  }
}

void Error_Handler(void)
{
  while(1)
  {
  }
}

/************************ (C) COPYRIGHT STMicroelectronics *****END OF FILE****/

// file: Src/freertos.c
/**
  ******************************************************************************
  * File Name          : freertos.c
  * Description        : Code for freertos applications
  ******************************************************************************
  *
  * Copyright (c) 2017 STMicroelectronics International N.V.
  * All rights reserved.
  *
  * Redistribution and use in source and binary forms, with or without
  * modification, are permitted, provided that the following conditions are met:
  *
  * 1. Redistribution of source code must retain the above copyright notice,
  *    this list of conditions and the following disclaimer.
  * 2. Redistributions in binary form must reproduce the above copyright notice,
  *    this list of conditions and the following disclaimer in the documentation
  *    and/or other materials provided with the distribution.
  * 3. Neither the name of STMicroelectronics nor the names of other
  *    contributors to this software may be used to endorse or promote products
  *    derived from this software without specific written permission.
  * 4. This software, including modifications and/or derivative works of this
  *    software, must execute solely and exclusively on microcontroller or
  *    microprocessor devices manufactured by or for STMicroelectronics.
  * 5. Redistribution and use of this software other than as permitted under
  *    this license is void and will automatically terminate your rights under
  *    this license.
  *
  * THIS SOFTWARE IS PROVIDED BY STMICROELECTRONICS AND CONTRIBUTORS "AS IS"
  * AND ANY EXPRESS, IMPLIED OR STATUTORY WARRANTIES, INCLUDING, BUT NOT
  * LIMITED TO, THE IMPLIED WARRANTIES OF MERCHANTABILITY, FITNESS FOR A
  * PARTICULAR PURPOSE AND NON-INFRINGEMENT OF THIRD PARTY INTELLECTUAL PROPERTY
  * RIGHTS ARE DISCLAIMED TO THE FULLEST EXTENT PERMITTED BY LAW. IN NO EVENT
  * SHALL STMICROELECTRONICS OR CONTRIBUTORS BE LIABLE FOR ANY DIRECT, INDIRECT,
  * INCIDENTAL, SPECIAL, EXEMPLARY, OR CONSEQUENTIAL DAMAGES (INCLUDING, BUT NOT
  * LIMITED TO, PROCUREMENT OF SUBSTITUTE GOODS OR SERVICES; LOSS OF USE, DATA,
  * OR PROFITS; OR BUSINESS INTERRUPTION) HOWEVER CAUSED AND ON ANY THEORY OF
  * LIABILITY, WHETHER IN CONTRACT, STRICT LIABILITY, OR TORT (INCLUDING
  * NEGLIGENCE OR OTHERWISE) ARISING IN ANY WAY OUT OF THE USE OF THIS SOFTWARE,
  * EVEN IF ADVISED OF THE POSSIBILITY OF SUCH DAMAGE.
  *
  ******************************************************************************
  */

#include "FreeRTOS.h"
#include "task.h"
#include "cmsis_os.h"

/* USER CODE BEGIN Includes */
#include "stm32f7xx_hal.h"

/* USER CODE END Includes */

osThreadId defaultTaskHandle;
osThreadId BlinkyTaskHandle;

void StartDefaultTask(void const * argument);
void ExecBlinkyTask(void const * argument);

extern void MX_LWIP_Init(void);
void MX_FREERTOS_Init(void); /* (MISRA C 2004 rule 8.1) */

/* Hook prototypes */

/* Init FreeRTOS */

void MX_FREERTOS_Init(void) {

  /* Create the thread(s) */
  /* definition and creation of defaultTask */
  osThreadDef(defaultTask, StartDefaultTask, osPriorityNormal, 0, 128);
  defaultTaskHandle = osThreadCreate(osThread(defaultTask), NULL);

  /* definition and creation of BlinkyTask */
  osThreadDef(BlinkyTask, ExecBlinkyTask, osPriorityIdle, 0, 128);
  BlinkyTaskHandle = osThreadCreate(osThread(BlinkyTask), NULL);

}

/* StartDefaultTask function */
void StartDefaultTask(void const * argument)
{
  /* init code for LWIP */
  MX_LWIP_Init();

  for(;;)
  {
    osDelay(1);
  }
}

/* ExecBlinkyTask function */
void ExecBlinkyTask(void const * argument)
{
  /* USER CODE BEGIN ExecBlinkyTask */
  /* Infinite loop */
  for(;;)
  {
	  HAL_GPIO_TogglePin(USER_LED_GPIO_Port, USER_LED_Pin);
	  __NOP();
	  vTaskDelay(250);
  }
  /* USER CODE END ExecBlinkyTask */
}

/************************ (C) COPYRIGHT STMicroelectronics *****END OF FILE****/
